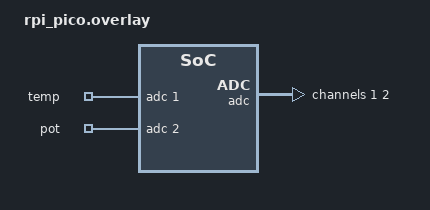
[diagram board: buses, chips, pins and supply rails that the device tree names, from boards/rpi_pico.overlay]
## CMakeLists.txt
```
cmake_minimum_required(VERSION 3.20.0)

find_package(Zephyr REQUIRED HINTS $ENV{ZEPHYR_BASE})

project(adc_check)

target_sources(app PRIVATE src/main.c)
```

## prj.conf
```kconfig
CONFIG_ADC=y
CONFIG_SERIAL=y
CONFIG_PRINTK=y

CONFIG_CDC_ACM_SERIAL_INITIALIZE_AT_BOOT=y
CONFIG_USB_DEVICE_STACK_NEXT=y

CONFIG_CBPRINTF_FP_SUPPORT=y
```

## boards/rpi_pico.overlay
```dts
/{
    myadcs: zephyr,user{
        io-channels = <&adc 1>, <&adc 2>;
        io-channel-names = "temp", "pot" ;
    };

    aliases{
        myadc = &myadcs;  
    };
};

&adc{
    #size-cells = <0>;
    #address-cells = <1>;
    status = "okay";

    channel@1{
        reg = <1>;
        zephyr,gain = "ADC_GAIN_1";
        zephyr,reference = "ADC_REF_INTERNAL";
        zephyr,acquisition-time = <ADC_ACQ_TIME_DEFAULT>;
        zephyr,resolution = <12>;
    };

    channel@2{
        reg = <2>;
        zephyr,gain = "ADC_GAIN_1";
        zephyr,reference = "ADC_REF_INTERNAL";
        zephyr,acquisition-time = <ADC_ACQ_TIME_DEFAULT>;
        zephyr,resolution = <12>;
    };
};
```

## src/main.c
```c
#include <zephyr/kernel.h>
#include <zephyr/devicetree.h>
#include <zephyr/drivers/adc.h>

#define ADC_NODE DT_ALIAS(myadc)

static const struct adc_dt_spec temp_sen = ADC_DT_SPEC_GET_BY_NAME(ADC_NODE, temp);
static const struct adc_dt_spec pot = ADC_DT_SPEC_GET_BY_NAME(ADC_NODE, pot);

uint16_t raw_temp[2];
uint16_t raw_pot[2];

static struct adc_sequence seq_temp = {
    .buffer = raw_temp,
    .buffer_size = sizeof(raw_temp),
};

static struct adc_sequence seq_pot = {
    .buffer = raw_pot,
    .buffer_size = sizeof(raw_pot),
};

int main(){

    uint32_t raw_temp_d;
    uint32_t raw_pot_d;

    float volt_temp_f;
    float volt_pot_f;

    float temperature;
    int degree;

    adc_sequence_init_dt(&temp_sen, &seq_temp);
    adc_sequence_init_dt(&pot, &seq_pot);

    while(1){

        adc_read_dt(&temp_sen, &seq_temp);
        adc_read_dt(&pot, &seq_pot);

        raw_temp_d = raw_temp[0];
        raw_pot_d = raw_pot[0];

        volt_temp_f = ((float)raw_temp_d*3.3)/4095;
        volt_pot_f = ((float)raw_pot_d*3.3)/4095;

        temperature = ((float)raw_temp_d*330)/4095;
        degree = ((float)raw_pot_d*360)/4095;

        printk("Raw value of a1: %d Voltage of a1: %.2f Temperature: %.2f\n", (int)raw_temp_d, volt_temp_f, temperature);
        printk("Raw value of a2: %d Voltage of a2: %.2f Degree: %d \n", (int)raw_pot_d, volt_pot_f, degree);

       
        k_msleep(500);
    }

}
```
